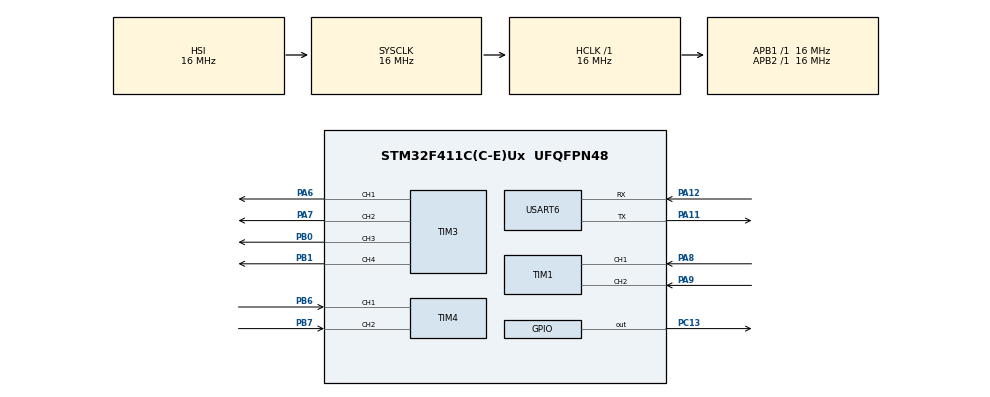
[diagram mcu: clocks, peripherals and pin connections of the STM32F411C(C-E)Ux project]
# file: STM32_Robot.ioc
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Mcu.Family=STM32F4
Mcu.Name=STM32F411C(C-E)Ux
Mcu.Package=UFQFPN48
NVIC.PriorityGroup=NVIC_PRIORITYGROUP_4
NVIC.USART6_IRQn=true\:0\:0\:false\:false\:true\:true\:true\:true
PA11.Mode=Asynchronous
PA11.Signal=USART6_TX
PA12.Mode=Asynchronous
PA12.Signal=USART6_RX
PA13.Mode=Serial_Wire
PA13.Signal=SYS_JTMS-SWDIO
PA14.Mode=Serial_Wire
PA14.Signal=SYS_JTCK-SWCLK
PA6.Signal=S_TIM3_CH1
PA7.Signal=S_TIM3_CH2
PA8.Signal=S_TIM1_CH1
PA9.Signal=S_TIM1_CH2
PB0.Signal=S_TIM3_CH3
PB1.Signal=S_TIM3_CH4
PB6.Signal=S_TIM4_CH1
PB7.Signal=S_TIM4_CH2
PC13-ANTI_TAMP.Signal=GPIO_Output
ProjectManager.HeapSize=0x200
ProjectManager.StackSize=0x400
ProjectManager.TargetToolchain=CMake
RCC.AHBFreq_Value=16000000
RCC.APB1Freq_Value=16000000
RCC.APB2Freq_Value=16000000
RCC.CortexFreq_Value=16000000
RCC.HSE_VALUE=25000000
RCC.HSI_VALUE=16000000
RCC.LSE_VALUE=32768
RCC.SYSCLKFreq_VALUE=16000000
RCC.VCOOutputFreq_Value=192000000
SH.S_TIM1_CH1.0=TIM1_CH1,Encoder_Interface
SH.S_TIM1_CH2.0=TIM1_CH2,Encoder_Interface
SH.S_TIM3_CH1.0=TIM3_CH1,PWM Generation1 CH1
SH.S_TIM3_CH2.0=TIM3_CH2,PWM Generation2 CH2
SH.S_TIM3_CH3.0=TIM3_CH3,PWM Generation3 CH3
SH.S_TIM3_CH4.0=TIM3_CH4,PWM Generation4 CH4
SH.S_TIM4_CH1.0=TIM4_CH1,Encoder_Interface
SH.S_TIM4_CH2.0=TIM4_CH2,Encoder_Interface
TIM3.Channel-PWM\ Generation1\ CH1=TIM_CHANNEL_1
TIM3.Channel-PWM\ Generation2\ CH2=TIM_CHANNEL_2
TIM3.Channel-PWM\ Generation3\ CH3=TIM_CHANNEL_3
TIM3.Channel-PWM\ Generation4\ CH4=TIM_CHANNEL_4
USART6.Parity=PARITY_NONE
USART6.VirtualMode=VM_ASYNC
USART6.WordLength=WORDLENGTH_8B
board=custom

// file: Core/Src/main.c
/* USER CODE BEGIN Header */
/**
  ******************************************************************************
  * @file           : main.c
  * @brief          : Main program body
  ******************************************************************************
  * @attention
  *
  * Copyright (c) 2026 STMicroelectronics.
  * All rights reserved.
  *
  * This software is licensed under terms that can be found in the LICENSE file
  * in the root directory of this software component.
  * If no LICENSE file comes with this software, it is provided AS-IS.
  *
  ******************************************************************************
  */
/* USER CODE END Header */
#include "main.h"

/* USER CODE BEGIN Includes */
#include "robot_app.h"
#include "stm32f4xx_hal_def.h"
#include "stm32f4xx_hal_uart.h"
/* USER CODE END Includes */

TIM_HandleTypeDef htim1;
TIM_HandleTypeDef htim3;
TIM_HandleTypeDef htim4;

UART_HandleTypeDef huart6;

void SystemClock_Config(void);
static void MX_GPIO_Init(void);
static void MX_TIM1_Init(void);
static void MX_TIM4_Init(void);
static void MX_USART6_UART_Init(void);
static void MX_TIM3_Init(void);

int main(void)
{

  /* MCU Configuration--------------------------------------------------------*/

  /* Reset of all peripherals, Initializes the Flash interface and the Systick. */

  HAL_Init();

  /* Configure the system clock */
  SystemClock_Config();

  /* Initialize all configured peripherals */
  MX_GPIO_Init();
  MX_TIM1_Init();
  MX_TIM4_Init();
  MX_USART6_UART_Init();
  MX_TIM3_Init();
  /* USER CODE BEGIN 2 */
  my_robot_app();
  /* USER CODE END 2 */

  /* Infinite loop */
  while (1)
  {
  }

}

void SystemClock_Config(void)
{
  RCC_OscInitTypeDef RCC_OscInitStruct = {0};
  RCC_ClkInitTypeDef RCC_ClkInitStruct = {0};

  /** Configure the main internal regulator output voltage
  */
  __HAL_RCC_PWR_CLK_ENABLE();
  __HAL_PWR_VOLTAGESCALING_CONFIG(PWR_REGULATOR_VOLTAGE_SCALE1);

  /** Initializes the RCC Oscillators according to the specified parameters
  * in the RCC_OscInitTypeDef structure.
  */
  RCC_OscInitStruct.OscillatorType = RCC_OSCILLATORTYPE_HSI;
  RCC_OscInitStruct.HSIState = RCC_HSI_ON;
  RCC_OscInitStruct.HSICalibrationValue = RCC_HSICALIBRATION_DEFAULT;
  RCC_OscInitStruct.PLL.PLLState = RCC_PLL_NONE;
  if (HAL_RCC_OscConfig(&RCC_OscInitStruct) != HAL_OK)
  {
    Error_Handler();
  }

  /** Initializes the CPU, AHB and APB buses clocks
  */
  RCC_ClkInitStruct.ClockType = RCC_CLOCKTYPE_HCLK|RCC_CLOCKTYPE_SYSCLK
                              |RCC_CLOCKTYPE_PCLK1|RCC_CLOCKTYPE_PCLK2;
  RCC_ClkInitStruct.SYSCLKSource = RCC_SYSCLKSOURCE_HSI;
  RCC_ClkInitStruct.AHBCLKDivider = RCC_SYSCLK_DIV1;
  RCC_ClkInitStruct.APB1CLKDivider = RCC_HCLK_DIV1;
  RCC_ClkInitStruct.APB2CLKDivider = RCC_HCLK_DIV1;

  if (HAL_RCC_ClockConfig(&RCC_ClkInitStruct, FLASH_LATENCY_0) != HAL_OK)
  {
    Error_Handler();
  }
}

static void MX_TIM1_Init(void)
{

  TIM_Encoder_InitTypeDef sConfig = {0};
  TIM_MasterConfigTypeDef sMasterConfig = {0};

  htim1.Instance = TIM1;
  htim1.Init.Prescaler = 0;
  htim1.Init.CounterMode = TIM_COUNTERMODE_UP;
  htim1.Init.Period = 65535;
  htim1.Init.ClockDivision = TIM_CLOCKDIVISION_DIV1;
  htim1.Init.RepetitionCounter = 0;
  htim1.Init.AutoReloadPreload = TIM_AUTORELOAD_PRELOAD_DISABLE;
  sConfig.EncoderMode = TIM_ENCODERMODE_TI1;
  sConfig.IC1Polarity = TIM_ICPOLARITY_RISING;
  sConfig.IC1Selection = TIM_ICSELECTION_DIRECTTI;
  sConfig.IC1Prescaler = TIM_ICPSC_DIV1;
  sConfig.IC1Filter = 0;
  sConfig.IC2Polarity = TIM_ICPOLARITY_RISING;
  sConfig.IC2Selection = TIM_ICSELECTION_DIRECTTI;
  sConfig.IC2Prescaler = TIM_ICPSC_DIV1;
  sConfig.IC2Filter = 0;
  if (HAL_TIM_Encoder_Init(&htim1, &sConfig) != HAL_OK)
  {
    Error_Handler();
  }
  sMasterConfig.MasterOutputTrigger = TIM_TRGO_RESET;
  sMasterConfig.MasterSlaveMode = TIM_MASTERSLAVEMODE_DISABLE;
  if (HAL_TIMEx_MasterConfigSynchronization(&htim1, &sMasterConfig) != HAL_OK)
  {
    Error_Handler();
  }

}

static void MX_TIM3_Init(void)
{

  TIM_MasterConfigTypeDef sMasterConfig = {0};
  TIM_OC_InitTypeDef sConfigOC = {0};

  htim3.Instance = TIM3;
  htim3.Init.Prescaler = 0;
  htim3.Init.CounterMode = TIM_COUNTERMODE_UP;
  htim3.Init.Period = 65535;
  htim3.Init.ClockDivision = TIM_CLOCKDIVISION_DIV1;
  htim3.Init.AutoReloadPreload = TIM_AUTORELOAD_PRELOAD_DISABLE;
  if (HAL_TIM_PWM_Init(&htim3) != HAL_OK)
  {
    Error_Handler();
  }
  sMasterConfig.MasterOutputTrigger = TIM_TRGO_RESET;
  sMasterConfig.MasterSlaveMode = TIM_MASTERSLAVEMODE_DISABLE;
  if (HAL_TIMEx_MasterConfigSynchronization(&htim3, &sMasterConfig) != HAL_OK)
  {
    Error_Handler();
  }
  sConfigOC.OCMode = TIM_OCMODE_PWM1;
  sConfigOC.Pulse = 0;
  sConfigOC.OCPolarity = TIM_OCPOLARITY_HIGH;
  sConfigOC.OCFastMode = TIM_OCFAST_DISABLE;
  if (HAL_TIM_PWM_ConfigChannel(&htim3, &sConfigOC, TIM_CHANNEL_1) != HAL_OK)
  {
    Error_Handler();
  }
  if (HAL_TIM_PWM_ConfigChannel(&htim3, &sConfigOC, TIM_CHANNEL_2) != HAL_OK)
  {
    Error_Handler();
  }
  if (HAL_TIM_PWM_ConfigChannel(&htim3, &sConfigOC, TIM_CHANNEL_3) != HAL_OK)
  {
    Error_Handler();
  }
  if (HAL_TIM_PWM_ConfigChannel(&htim3, &sConfigOC, TIM_CHANNEL_4) != HAL_OK)
  {
    Error_Handler();
  }
  HAL_TIM_MspPostInit(&htim3);

}

static void MX_TIM4_Init(void)
{

  TIM_Encoder_InitTypeDef sConfig = {0};
  TIM_MasterConfigTypeDef sMasterConfig = {0};

  htim4.Instance = TIM4;
  htim4.Init.Prescaler = 0;
  htim4.Init.CounterMode = TIM_COUNTERMODE_UP;
  htim4.Init.Period = 65535;
  htim4.Init.ClockDivision = TIM_CLOCKDIVISION_DIV1;
  htim4.Init.AutoReloadPreload = TIM_AUTORELOAD_PRELOAD_DISABLE;
  sConfig.EncoderMode = TIM_ENCODERMODE_TI1;
  sConfig.IC1Polarity = TIM_ICPOLARITY_RISING;
  sConfig.IC1Selection = TIM_ICSELECTION_DIRECTTI;
  sConfig.IC1Prescaler = TIM_ICPSC_DIV1;
  sConfig.IC1Filter = 0;
  sConfig.IC2Polarity = TIM_ICPOLARITY_RISING;
  sConfig.IC2Selection = TIM_ICSELECTION_DIRECTTI;
  sConfig.IC2Prescaler = TIM_ICPSC_DIV1;
  sConfig.IC2Filter = 0;
  if (HAL_TIM_Encoder_Init(&htim4, &sConfig) != HAL_OK)
  {
    Error_Handler();
  }
  sMasterConfig.MasterOutputTrigger = TIM_TRGO_RESET;
  sMasterConfig.MasterSlaveMode = TIM_MASTERSLAVEMODE_DISABLE;
  if (HAL_TIMEx_MasterConfigSynchronization(&htim4, &sMasterConfig) != HAL_OK)
  {
    Error_Handler();
  }

}

static void MX_USART6_UART_Init(void)
{

  huart6.Instance = USART6;
  huart6.Init.BaudRate = 115200;
  huart6.Init.WordLength = UART_WORDLENGTH_8B;
  huart6.Init.StopBits = UART_STOPBITS_1;
  huart6.Init.Parity = UART_PARITY_NONE;
  huart6.Init.Mode = UART_MODE_TX_RX;
  huart6.Init.HwFlowCtl = UART_HWCONTROL_NONE;
  huart6.Init.OverSampling = UART_OVERSAMPLING_16;
  if (HAL_UART_Init(&huart6) != HAL_OK)
  {
    Error_Handler();
  }

}

static void MX_GPIO_Init(void)
{
  GPIO_InitTypeDef GPIO_InitStruct = {0};

  /* GPIO Ports Clock Enable */
  __HAL_RCC_GPIOC_CLK_ENABLE();
  __HAL_RCC_GPIOA_CLK_ENABLE();
  __HAL_RCC_GPIOB_CLK_ENABLE();

  /*Configure GPIO pin Output Level */
  HAL_GPIO_WritePin(GPIOC, GPIO_PIN_13, GPIO_PIN_RESET);

  /*Configure GPIO pin : PC13 */
  GPIO_InitStruct.Pin = GPIO_PIN_13;
  GPIO_InitStruct.Mode = GPIO_MODE_OUTPUT_PP;
  GPIO_InitStruct.Pull = GPIO_NOPULL;
  GPIO_InitStruct.Speed = GPIO_SPEED_FREQ_LOW;
  HAL_GPIO_Init(GPIOC, &GPIO_InitStruct);

}

void Error_Handler(void)
{
  __disable_irq();
  while (1)
  {
  }
}
